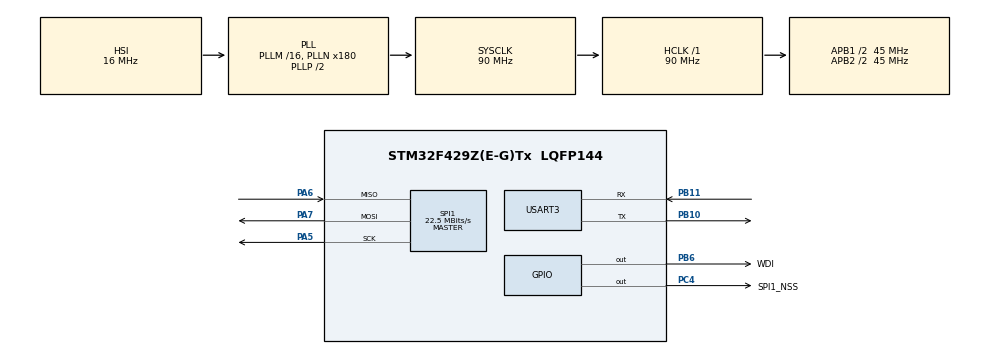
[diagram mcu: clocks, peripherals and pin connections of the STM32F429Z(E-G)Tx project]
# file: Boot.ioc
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Mcu.Family=STM32F4
NVIC.USART3_IRQn=true\:0\:0\:false\:false\:true\:true\:true
PA6.Mode=Full_Duplex_Master
RCC.CortexFreq_Value=90000000
PA7.Mode=Full_Duplex_Master
SPI1.VirtualType=VM_MASTER
PB10.Mode=Asynchronous
PC4.Signal=GPIO_Output
PB6.GPIO_Label=WDI
RCC.APB1CLKDivider=RCC_HCLK_DIV2
PB11.Signal=USART3_RX
RCC.SYSCLKSource=RCC_SYSCLKSOURCE_PLLCLK
ProjectManager.StackSize=0x400
PA13.Signal=SYS_JTMS-SWDIO
PB11.Mode=Asynchronous
ProjectManager.TargetToolchain=MDK-ARM V5
SPI1.Direction=SPI_DIRECTION_2LINES
RCC.HCLKFreq_Value=90000000
RCC.APB2TimFreq_Value=90000000
PB6.Signal=GPIO_Output
SPI1.CalculateBaudRate=22.5 MBits/s
RCC.AHBFreq_Value=90000000
PB10.Signal=USART3_TX
PA5.Signal=SPI1_SCK
RCC.HSE_VALUE=8000000
board=custom
RCC.VCOOutputFreq_Value=180000000
RCC.APB2Freq_Value=45000000
PC4.GPIO_Label=SPI1_NSS
SPI1.Mode=SPI_MODE_MASTER
PA14.Mode=Serial_Wire
PA13.Mode=Serial_Wire
Mcu.Name=STM32F429Z(E-G)Tx
RCC.48MHZClocksFreq_Value=45000000
RCC.SYSCLKFreq_VALUE=90000000
Mcu.Package=LQFP144
PA6.Signal=SPI1_MISO
USART3.VirtualMode=VM_ASYNC
PA14.Signal=SYS_JTCK-SWCLK
ProjectManager.HeapSize=0x200
RCC.HSI_VALUE=16000000
NVIC.PriorityGroup=NVIC_PRIORITYGROUP_4
RCC.APB2CLKDivider=RCC_HCLK_DIV2
RCC.PLLN=180
RCC.APB1TimFreq_Value=90000000
RCC.APB1Freq_Value=45000000
SPI1.BaudRatePrescaler=SPI_BAUDRATEPRESCALER_2
PA5.Mode=Full_Duplex_Master
PA7.Signal=SPI1_MOSI

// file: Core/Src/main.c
/* USER CODE BEGIN Header */
/**
  ******************************************************************************
  * @file           : main.c
  * @brief          : Main program body
  ******************************************************************************
  * @attention
  *
  * <h2><center>&copy; Copyright (c) 2021 STMicroelectronics.
  * All rights reserved.</center></h2>
  *
  * This software component is licensed by ST under BSD 3-Clause license,
  * the "License"; You may not use this file except in compliance with the
  * License. You may obtain a copy of the License at:
  *                        opensource.org/licenses/BSD-3-Clause
  *
  ******************************************************************************
  */
/* USER CODE END Header */
#include "main.h"
#include "spi.h"
#include "usart.h"
#include "gpio.h"

/* USER CODE BEGIN Includes */
#include "apps.h"
/* USER CODE END Includes */

void SystemClock_Config(void);

int main(void)
{

  /* MCU Configuration--------------------------------------------------------*/

  /* Reset of all peripherals, Initializes the Flash interface and the Systick. */
  HAL_Init();

  /* Configure the system clock */
  SystemClock_Config();

  /* Initialize all configured peripherals */
  MX_GPIO_Init();
  MX_SPI1_Init();
  MX_USART3_UART_Init();
  /* USER CODE BEGIN 2 */
  Main_Init();
  /* USER CODE END 2 */

  /* Infinite loop */
  while (1)
  {

    /* USER CODE BEGIN 3 */
    Main_Process();
  }
  /* USER CODE END 3 */
}

void SystemClock_Config(void)
{
  RCC_OscInitTypeDef RCC_OscInitStruct = {0};
  RCC_ClkInitTypeDef RCC_ClkInitStruct = {0};

  /** Configure the main internal regulator output voltage
  */
  __HAL_RCC_PWR_CLK_ENABLE();
  __HAL_PWR_VOLTAGESCALING_CONFIG(PWR_REGULATOR_VOLTAGE_SCALE3);
  /** Initializes the RCC Oscillators according to the specified parameters
  * in the RCC_OscInitTypeDef structure.
  */
  RCC_OscInitStruct.OscillatorType = RCC_OSCILLATORTYPE_HSI;
  RCC_OscInitStruct.HSIState = RCC_HSI_ON;
  RCC_OscInitStruct.HSICalibrationValue = RCC_HSICALIBRATION_DEFAULT;
  RCC_OscInitStruct.PLL.PLLState = RCC_PLL_ON;
  RCC_OscInitStruct.PLL.PLLSource = RCC_PLLSOURCE_HSI;
  RCC_OscInitStruct.PLL.PLLM = 16;
  RCC_OscInitStruct.PLL.PLLN = 180;
  RCC_OscInitStruct.PLL.PLLP = RCC_PLLP_DIV2;
  RCC_OscInitStruct.PLL.PLLQ = 4;
  if (HAL_RCC_OscConfig(&RCC_OscInitStruct) != HAL_OK)
  {
    Error_Handler();
  }
  /** Activate the Over-Drive mode
  */
  if (HAL_PWREx_EnableOverDrive() != HAL_OK)
  {
    Error_Handler();
  }
  /** Initializes the CPU, AHB and APB buses clocks
  */
  RCC_ClkInitStruct.ClockType = RCC_CLOCKTYPE_HCLK|RCC_CLOCKTYPE_SYSCLK
                              |RCC_CLOCKTYPE_PCLK1|RCC_CLOCKTYPE_PCLK2;
  RCC_ClkInitStruct.SYSCLKSource = RCC_SYSCLKSOURCE_PLLCLK;
  RCC_ClkInitStruct.AHBCLKDivider = RCC_SYSCLK_DIV1;
  RCC_ClkInitStruct.APB1CLKDivider = RCC_HCLK_DIV2;
  RCC_ClkInitStruct.APB2CLKDivider = RCC_HCLK_DIV2;

  if (HAL_RCC_ClockConfig(&RCC_ClkInitStruct, FLASH_LATENCY_2) != HAL_OK)
  {
    Error_Handler();
  }
}

void Error_Handler(void)
{
  __disable_irq();
  while (1)
  {
  }
}

/************************ (C) COPYRIGHT STMicroelectronics *****END OF FILE****/
